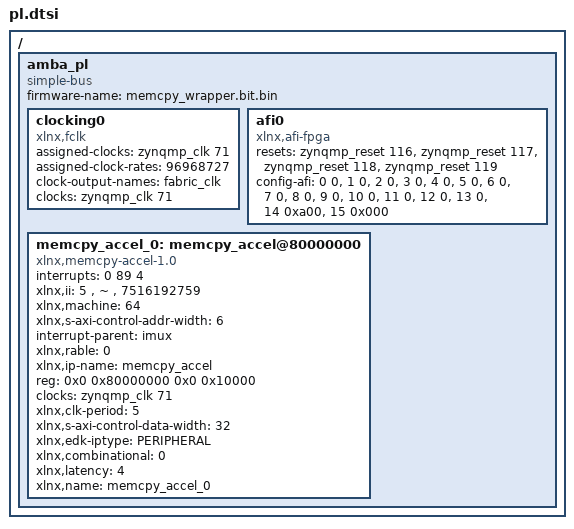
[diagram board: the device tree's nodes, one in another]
/ {
	amba_pl: amba_pl {
		ranges;
		compatible = "simple-bus";
		#address-cells = <2>;
		#size-cells = <2>;
		firmware-name = "memcpy_wrapper.bit.bin";
		clocking0: clocking0 {
			compatible = "xlnx,fclk";
			status = "okay";
			assigned-clocks = <&zynqmp_clk 71>;
			assigned-clock-rates = <96968727>;
			#clock-cells = <0>;
			clock-output-names = "fabric_clk";
			clocks = <&zynqmp_clk 71>;
		};
		afi0: afi0 {
			status = "okay";
			compatible = "xlnx,afi-fpga";
			resets = <&zynqmp_reset 116>, <&zynqmp_reset 117>, <&zynqmp_reset 118>, <&zynqmp_reset 119>;
			config-afi = < 0 0>, <1 0>, <2 0>, <3 0>, <4 0>, <5 0>, <6 0>, <7 0>, <8 0>, <9 0>, <10 0>, <11 0>, <12 0>, <13 0>, <14 0xa00>, <15 0x000>;
		};
		memcpy_accel_0: memcpy_accel@80000000 {
			interrupts = < 0 89 4 >;
			compatible = "xlnx,memcpy-accel-1.0";
			xlnx,ii = "5 , ~ , 7516192759";
			xlnx,machine = <64>;
			xlnx,s-axi-control-addr-width = <6>;
			interrupt-parent = <&imux>;
			xlnx,rable = <0>;
			xlnx,ip-name = "memcpy_accel";
			reg = <0x0 0x80000000 0x0 0x10000>;
			clocks = <&zynqmp_clk 71>;
			xlnx,clk-period = <5>;
			xlnx,s-axi-control-data-width = <32>;
			xlnx,edk-iptype = "PERIPHERAL";
			status = "okay";
			clock-names = "ap_clk";
			interrupt-names = "interrupt";
			xlnx,combinational = <0>;
			xlnx,latency = <4>;
			xlnx,name = "memcpy_accel_0";
		};
	};
};
